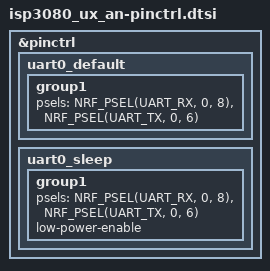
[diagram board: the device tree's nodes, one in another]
&pinctrl {
	/omit-if-no-ref/ uart0_default: uart0_default {
		group1 {
			psels = <NRF_PSEL(UART_RX, 0, 8)>,
					<NRF_PSEL(UART_TX, 0, 6)>;
		};
	};

	/omit-if-no-ref/ uart0_sleep: uart0_sleep {
		group1 {
			psels = <NRF_PSEL(UART_RX, 0, 8)>,
					<NRF_PSEL(UART_TX, 0, 6)>;
			low-power-enable;
		};
	};
};
